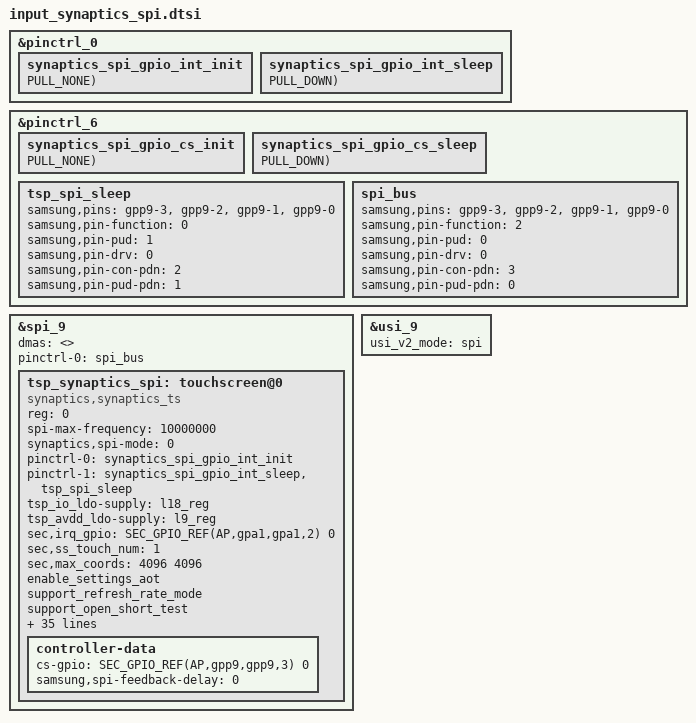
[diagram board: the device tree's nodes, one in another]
&pinctrl_0 {
	synaptics_spi_gpio_int_init: synaptics_spi_gpio_int_init {
		GPIO_CONFIG_PUD(AP,gpa1,gpa1,2, FUNC_INPUT_WAKEUP, PULL_NONE);
	};

	synaptics_spi_gpio_int_sleep: synaptics_spi_gpio_int_sleep {
		GPIO_CONFIG_PUD(AP,gpa1,gpa1,2, FUNC_INPUT, PULL_DOWN);
	};
};

&pinctrl_6 {
	synaptics_spi_gpio_cs_init: synaptics_spi_gpio_cs_init {
		GPIO_CONFIG_PUD(AP,gpp9,gpp9,3, FUNC_OUTPUT_HIGH, PULL_NONE);
	};

	synaptics_spi_gpio_cs_sleep: synaptics_spi_gpio_cs_sleep {
		GPIO_CONFIG_PUD(AP,gpp9,gpp9,3, FUNC_OUTPUT_LOW, PULL_DOWN);
	};
};

&spi_9 {
	#address-cells = <1>;
	#size-cells = <0>;
	status = "ok";
	dmas = <>;

	tsp_synaptics_spi: touchscreen@0 {
		status = "ok";
		compatible = "synaptics,synaptics_ts";
		reg = <0>;
		spi-max-frequency = <10000000>;
		synaptics,spi-mode = <0>;
		pinctrl-names = "on_state", "off_state";
		pinctrl-0 = <&synaptics_spi_gpio_int_init &synaptics_spi_gpio_cs_init>;
		pinctrl-1 = <&synaptics_spi_gpio_int_sleep &synaptics_spi_gpio_cs_sleep>;
		tsp_io_ldo-supply = <&l18_reg>;
		tsp_avdd_ldo-supply = <&l9_reg>;
		sec,irq_gpio = <SEC_GPIO_REF(AP,gpa1,gpa1,2) 0>;
		/* This part is for firmware */
		sec,ss_touch_num = <1>;
		sec,max_coords = <4096 4096>; /* x y */

		enable_settings_aot;
		//support_dex_mode;
		//support_mis_calibration_test;
		//support_ear_detect_mode;
		support_refresh_rate_mode;
		support_open_short_test;
		//support_fod;
		//support_fod_lp_mode;
		//support_vrr;
		sec,enable_sysinput_enabled;
		controller-data {
			cs-gpio = <SEC_GPIO_REF(AP,gpp9,gpp9,3) 0>;
			samsung,spi-feedback-delay = <0>;
		};
	};
};


/* /home/dpi/qb5_8814/workspace/P4_1716/android/kernel/kmodule/input/sec_input_2023/touchscreen/synaptics/common_u/dts_spi/input-lsi-tsp-synaptics-spi.e2s.dtsi */
&pinctrl_6 {
	tsp_spi_sleep: tsp_spi_sleep {
		samsung,pins = "gpp9-3", "gpp9-2", "gpp9-1", "gpp9-0";
		samsung,pin-function = <0>;
		samsung,pin-pud = <1>;
		samsung,pin-drv = <0>;
		samsung,pin-con-pdn = <2>;
		samsung,pin-pud-pdn = <1>;
	};

	spi_bus: spi_bus {
		samsung,pins = "gpp9-3", "gpp9-2", "gpp9-1", "gpp9-0";
		samsung,pin-function = <2>;
		samsung,pin-pud = <0>;
		samsung,pin-drv = <0>;
		samsung,pin-con-pdn = <3>;
		samsung,pin-pud-pdn = <0>;
	};
};

&usi_9 {
	usi_v2_mode = "spi";
	status = "okay";
};

&spi_9 {
	pinctrl-0 = <&spi_bus>;
};

&tsp_synaptics_spi {
	pinctrl-0 = <&synaptics_spi_gpio_int_init>;
	pinctrl-1 = <&synaptics_spi_gpio_int_sleep &tsp_spi_sleep>;

	sec,gpio_spi_cs = <SEC_GPIO_REF(AP,gpp9,gpp9,3) 0>;
	sec,area-size = <133 266 341>;
	sec,bringup = <0>;

	sec,select_lcdid = <0x815400 0x819400>;
	sec,lcdid_mask = <0xFFFF00>;
	sec,firmware_name = "tsp_synaptics/s3916a_e2.bin", // 0x815440 0x815450
					"tsp_synaptics/s3916t_e2.bin"; // 0x819440 0x819450
	sec,tclm_level = <2>;
	sec,afe_base = <0x0007>;

	support_fod;
	support_vbus_notifier;
	support_dex_mode;
	support_mis_calibration_test;
	support_ear_detect_mode;
	support_open_short_test;
	enable_settings_aot;
	sec,enable_sysinput_enabled;
	sec,support_rawdata;
	sec,support_rawdata_motion_palm;
	support_gesture_uevent;
	work_queue_probe_enabled;

	synaptics,fw_delay = <6 120>;
	synaptics,power_on_delay = <100>;
	synaptics,support_immediate_cmd;
	sec,probe_queue_delay = <500>;

	sec_cmd,not_support_cmds = "set_scan_rate", "refresh_rate_mode", "set_note_mode";

	trusted-touch-mode = "vm_mode";
	touch-environment = "pvm";
	trusted-touch-type = "secondary";

	trusted-touch-spi-irq = <0x282>;
	trusted-touch-io-bases = <0xf102000 0xf103000 0xf176000 0xf177000 0xf137000 0x890000 0x810000>;
	trusted-touch-io-sizes = <0x1000 0x1000 0x1000 0x1000 0x1000 0x1000 0x4000>;
};
